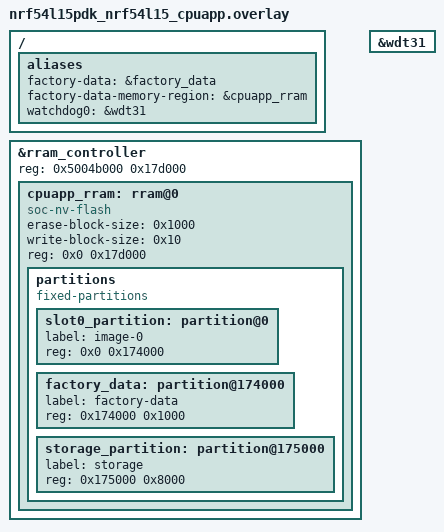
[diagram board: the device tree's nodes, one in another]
/*
 * Copyright (c) 2024 Nordic Semiconductor ASA
 *
 * SPDX-License-Identifier: LicenseRef-Nordic-5-Clause
 */

/ {
	aliases {
		factory-data = &factory_data;
		factory-data-memory-region = &cpuapp_rram;

		// Use watchdog wdt31 as the application watchdog
		watchdog0 = &wdt31;
	};
};

/delete-node/ &cpuapp_rram;

&rram_controller {
	reg = < 0x5004b000 0x17d000 >;

	cpuapp_rram: rram@0 {
		compatible = "soc-nv-flash";
		erase-block-size = < 0x1000 >;
		write-block-size = < 0x10 >;
		reg = < 0x0 0x17d000 >;
		partitions {
			compatible = "fixed-partitions";
			#address-cells = < 0x1 >;
			#size-cells = < 0x1 >;
			slot0_partition: partition@0 {
				label = "image-0";
				reg = < 0x0 0x174000 >;
			};
			factory_data: partition@174000 {
				label = "factory-data";
				reg = < 0x174000 0x1000 >;
			};
			storage_partition: partition@175000 {
				label = "storage";
				reg = < 0x175000 0x8000 >;
			};
		};
	};
};

&wdt31 {
	status = "okay";
};
